# ESP32-H4 register map
Vendor: ESPRESSIF SYSTEMS (SHANGHAI) CO., LTD.; Series: ESP32 H-Series; File version: 1
CPU: RV32IMAC r0p0, little endian, no MPU, no FPU, 0 interrupt priority bits
Address unit: 32 bits
Registers are 32-bit, read-write, reset 0x0 unless marked. A register's access mark holds for its fields unless they carry their own. Offsets are from the block's base; [hi:lo] are bit positions; {n}, {i} and the like mark numbered series.

## DMA — DMA (Direct Memory Access) Controller
Base 0x6001F000
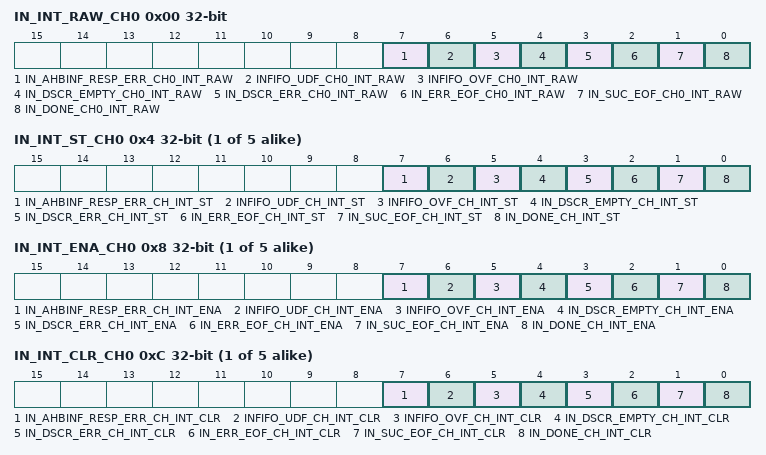
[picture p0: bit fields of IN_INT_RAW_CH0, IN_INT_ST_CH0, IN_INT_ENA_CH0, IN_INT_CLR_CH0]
0x00 IN_INT_RAW_CH0 — Raw interrupt status of RX channel 0
  [7] IN_AHBINF_RESP_ERR_CH0_INT_RAW — The raw interrupt status of AHB_DMA_IN_RESP_ERR_CH0_INT.
  [6] INFIFO_UDF_CH0_INT_RAW — The raw interrupt status of AHB_DMA_INFIFO_UDF_CH0_INT.
  [5] INFIFO_OVF_CH0_INT_RAW — The raw interrupt status of AHB_DMA_INFIFO_OVF_CH0_INT.
  [4] IN_DSCR_EMPTY_CH0_INT_RAW — The raw interrupt status of AHB_DMA_IN_DSCR_EMPTY_CH0_INT.
  [3] IN_DSCR_ERR_CH0_INT_RAW — The raw interrupt status of AHB_DMA_IN_DSCR_ERR_CH0_INT.
  [2] IN_ERR_EOF_CH0_INT_RAW — The raw interrupt status of AHB_DMA_IN_ERR_EOF_CH0_INT.
  [1] IN_SUC_EOF_CH0_INT_RAW — The raw interrupt status of AHB_DMA_IN_SUC_EOF_CH0_INT.
  [0] IN_DONE_CH0_INT_RAW — The raw interrupt status of AHB_DMA_IN_DONE_CH0_INT.
{0x4+0x10*i} IN_INT_ST_CH{i} (i=0..4) ro — Masked interrupt status of RX channel {i}
  [7] IN_AHBINF_RESP_ERR_CH_INT_ST — The masked interrupt status of AHB_DMA_IN_RESP_ERR_CH%s_INT.
  [6] INFIFO_UDF_CH_INT_ST — The masked interrupt status of AHB_DMA_INFIFO_UDF_CH%s_INT.
  [5] INFIFO_OVF_CH_INT_ST — The masked interrupt status of AHB_DMA_INFIFO_OVF_CH%s_INT.
  [4] IN_DSCR_EMPTY_CH_INT_ST — The masked interrupt status of AHB_DMA_IN_DSCR_EMPTY_CH%s_INT.
  [3] IN_DSCR_ERR_CH_INT_ST — The masked interrupt status of AHB_DMA_IN_DSCR_ERR_CH%s_INT.
  [2] IN_ERR_EOF_CH_INT_ST — The masked interrupt status of AHB_DMA_IN_ERR_EOF_CH%s_INT.
  [1] IN_SUC_EOF_CH_INT_ST — The masked interrupt status of AHB_DMA_IN_SUC_EOF_CH%s_INT.
  [0] IN_DONE_CH_INT_ST — The masked interrupt status of AHB_DMA_IN_DONE_CH%s_INT.
{0x8+0x10*i} IN_INT_ENA_CH{i} (i=0..4) — Interrupt enable bits of RX channel {i}
  [7] IN_AHBINF_RESP_ERR_CH_INT_ENA — Write 1 to enable AHB_DMA_IN_RESP_ERR_CH%s_INT.
  [6] INFIFO_UDF_CH_INT_ENA — Write 1 to enable AHB_DMA_INFIFO_UDF_CH%s_INT.
  [5] INFIFO_OVF_CH_INT_ENA — Write 1 to enable AHB_DMA_INFIFO_OVF_CH%s_INT.
  [4] IN_DSCR_EMPTY_CH_INT_ENA — Write 1 to enable AHB_DMA_IN_DSCR_EMPTY_CH%s_INT.
  [3] IN_DSCR_ERR_CH_INT_ENA — Write 1 to enable AHB_DMA_IN_DSCR_ERR_CH%s_INT.
  [2] IN_ERR_EOF_CH_INT_ENA — Write 1 to enable AHB_DMA_IN_ERR_EOF_CH%s_INT.
  [1] IN_SUC_EOF_CH_INT_ENA — Write 1 to enable AHB_DMA_IN_SUC_EOF_CH%s_INT.
  [0] IN_DONE_CH_INT_ENA — Write 1 to enable AHB_DMA_IN_DONE_CH%s_INT.
{0xC+0x10*i} IN_INT_CLR_CH{i} (i=0..4) wo — Interrupt clear bits of RX channel {i}
  [7] IN_AHBINF_RESP_ERR_CH_INT_CLR — Write 1 to clear AHB_DMA_IN_RESP_ERR_CH%s_INT.
  [6] INFIFO_UDF_CH_INT_CLR — Write 1 to clear AHB_DMA_INFIFO_UDF_CH%s_INT.
  [5] INFIFO_OVF_CH_INT_CLR — Write 1 to clear AHB_DMA_INFIFO_OVF_CH%s_INT.
  [4] IN_DSCR_EMPTY_CH_INT_CLR — Write 1 to clear AHB_DMA_IN_DSCR_EMPTY_CH%s_INT.
  [3] IN_DSCR_ERR_CH_INT_CLR — Write 1 to clear AHB_DMA_IN_DSCR_ERR_CH%s_INT.
  [2] IN_ERR_EOF_CH_INT_CLR — Write 1 to clear AHB_DMA_IN_ERR_EOF_CH%s_INT.
  [1] IN_SUC_EOF_CH_INT_CLR — Write 1 to clear AHB_DMA_IN_SUC_EOF_CH%s_INT.
  [0] IN_DONE_CH_INT_CLR — Write 1 to clear AHB_DMA_IN_DONE_CH%s_INT.
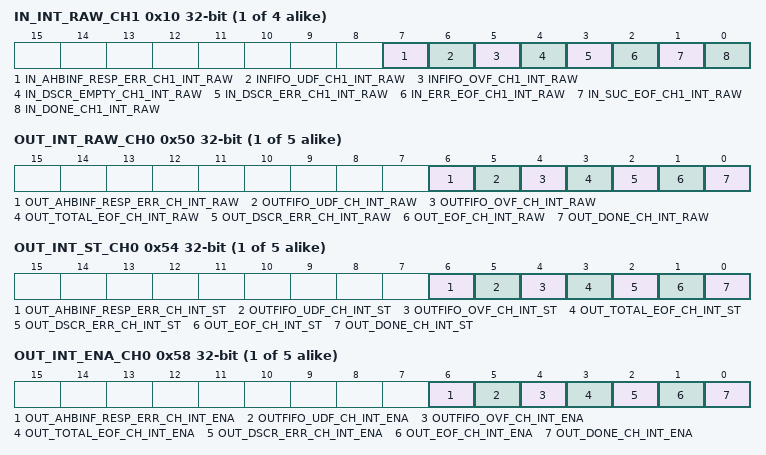
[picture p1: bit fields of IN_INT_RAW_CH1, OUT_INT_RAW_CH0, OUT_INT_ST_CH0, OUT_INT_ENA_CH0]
{0x0+0x10*i} IN_INT_RAW_CH{i} (i=1..4) — Raw interrupt status interrupt of RX channel {i}
  [7] IN_AHBINF_RESP_ERR_CH{i}_INT_RAW — The raw interrupt status of AHB_DMA_IN_RESP_ERR_CH{i}_INT.
  [6] INFIFO_UDF_CH{i}_INT_RAW — The raw interrupt status of AHB_DMA_INFIFO_UDF_CH{i}_INT.
  [5] INFIFO_OVF_CH{i}_INT_RAW — The raw interrupt status of AHB_DMA_INFIFO_OVF_CH{i}_INT.
  [4] IN_DSCR_EMPTY_CH{i}_INT_RAW — The raw interrupt status of AHB_DMA_IN_DSCR_EMPTY_CH{i}_INT.
  [3] IN_DSCR_ERR_CH{i}_INT_RAW — The raw interrupt status of AHB_DMA_IN_DSCR_ERR_CH{i}_INT.
  [2] IN_ERR_EOF_CH{i}_INT_RAW — The raw interrupt status of AHB_DMA_IN_ERR_EOF_CH{i}_INT.
  [1] IN_SUC_EOF_CH{i}_INT_RAW — The raw interrupt status of AHB_DMA_IN_SUC_EOF_CH{i}_INT.
  [0] IN_DONE_CH{i}_INT_RAW — The raw interrupt status of AHB_DMA_IN_DONE_CH{i}_INT.
{0x50+0x10*i} OUT_INT_RAW_CH{i} (i=0..4) — Raw interrupt status of TX channel {i}
  [6] OUT_AHBINF_RESP_ERR_CH_INT_RAW — The raw interrupt status of AHB_DMA_OUT_RESP_ERR_CH%s_INT.
  [5] OUTFIFO_UDF_CH_INT_RAW — The raw interrupt status of AHB_DMA_OUTFIFO_UDF_CH%s_INT.
  [4] OUTFIFO_OVF_CH_INT_RAW — The raw interrupt status of AHB_DMA_OUTFIFO_OVF_CH%s_INT.
  [3] OUT_TOTAL_EOF_CH_INT_RAW — The raw interrupt status of AHB_DMA_OUT_TOTAL_EOF_CH%s_INT.
  [2] OUT_DSCR_ERR_CH_INT_RAW — The raw interrupt status of AHB_DMA_OUT_DSCR_ERR_CH%s_INT.
  [1] OUT_EOF_CH_INT_RAW — The raw interrupt status of AHB_DMA_OUT_EOF_CH%s_INT.
  [0] OUT_DONE_CH_INT_RAW — The raw interrupt status of AHB_DMA_OUT_DONE_CH%s_INT.
{0x54+0x10*i} OUT_INT_ST_CH{i} (i=0..4) ro — Masked interrupt status of TX channel {i}
  [6] OUT_AHBINF_RESP_ERR_CH_INT_ST — The masked interrupt status of AHB_DMA_OUT_RESP_ERR_CH%s_INT.
  [5] OUTFIFO_UDF_CH_INT_ST — The masked interrupt status of AHB_DMA_OUTFIFO_UDF_CH%s_INT.
  [4] OUTFIFO_OVF_CH_INT_ST — The masked interrupt status of AHB_DMA_OUTFIFO_OVF_CH%s_INT.
  [3] OUT_TOTAL_EOF_CH_INT_ST — The masked interrupt status of AHB_DMA_OUT_TOTAL_EOF_CH%s_INT.
  [2] OUT_DSCR_ERR_CH_INT_ST — The masked interrupt status of AHB_DMA_OUT_DSCR_ERR_CH%s_INT.
  [1] OUT_EOF_CH_INT_ST — The masked interrupt status of AHB_DMA_OUT_EOF_CH%s_INT.
  [0] OUT_DONE_CH_INT_ST — The masked interrupt status of AHB_DMA_OUT_DONE_CH%s_INT.
{0x58+0x10*i} OUT_INT_ENA_CH{i} (i=0..4) — Interrupt enable bits of TX channel {i}
  [6] OUT_AHBINF_RESP_ERR_CH_INT_ENA — Write 1 to enable AHB_DMA_OUT_RESP_ERR_CH%s_INT.
  [5] OUTFIFO_UDF_CH_INT_ENA — Write 1 to enable AHB_DMA_OUTFIFO_UDF_CH%s_INT.
  [4] OUTFIFO_OVF_CH_INT_ENA — Write 1 to enable AHB_DMA_OUTFIFO_OVF_CH%s_INT.
  [3] OUT_TOTAL_EOF_CH_INT_ENA — Write 1 to enable AHB_DMA_OUT_TOTAL_EOF_CH%s_INT.
  [2] OUT_DSCR_ERR_CH_INT_ENA — Write 1 to enable AHB_DMA_OUT_DSCR_ERR_CH%s_INT.
  [1] OUT_EOF_CH_INT_ENA — Write 1 to enable AHB_DMA_OUT_EOF_CH%s_INT.
  [0] OUT_DONE_CH_INT_ENA — Write 1 to enable AHB_DMA_OUT_DONE_CH%s_INT.
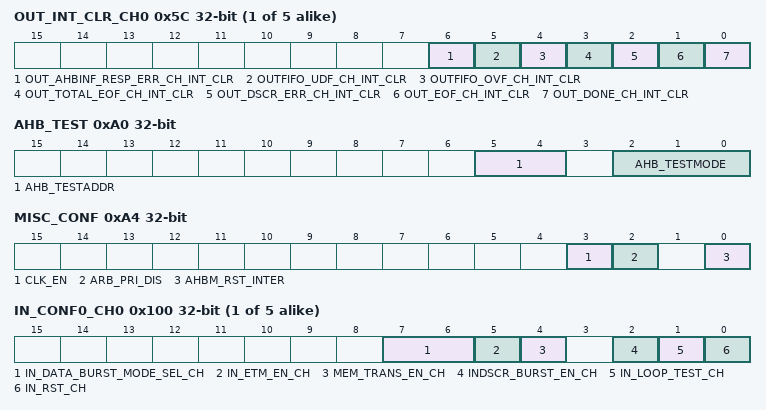
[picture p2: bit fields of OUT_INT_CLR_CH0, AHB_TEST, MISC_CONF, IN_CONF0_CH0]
{0x5C+0x10*i} OUT_INT_CLR_CH{i} (i=0..4) wo — Interrupt clear bits of TX channel {i}
  [6] OUT_AHBINF_RESP_ERR_CH_INT_CLR — Write 1 to clear AHB_DMA_OUT_RESP_ERR_CH%s_INT.
  [5] OUTFIFO_UDF_CH_INT_CLR — Write 1 to clear AHB_DMA_OUTFIFO_UDF_CH%s_INT.
  [4] OUTFIFO_OVF_CH_INT_CLR — Write 1 to clear AHB_DMA_OUTFIFO_OVF_CH%s_INT.
  [3] OUT_TOTAL_EOF_CH_INT_CLR — Write 1 to clear AHB_DMA_OUT_TOTAL_EOF_CH%s_INT.
  [2] OUT_DSCR_ERR_CH_INT_CLR — Write 1 to clear AHB_DMA_OUT_DSCR_ERR_CH%s_INT.
  [1] OUT_EOF_CH_INT_CLR — Write 1 to clear AHB_DMA_OUT_EOF_CH%s_INT.
  [0] OUT_DONE_CH_INT_CLR — Write 1 to clear AHB_DMA_OUT_DONE_CH%s_INT.
0xA0 AHB_TEST — reserved
  [5:4] AHB_TESTADDR — reserved
  [2:0] AHB_TESTMODE — reserved
0xA4 MISC_CONF — Miscellaneous register
  [3] CLK_EN — Configures clock gating.\\0: Support clock only when the application writes registers.\\ 1: Always force the clock on for registers.\\
  [2] ARB_PRI_DIS — Configures whether to disable the fixed-priority channel arbitration.\\0: Enable\\1: Disable\\
  [0] AHBM_RST_INTER — Write 1 and then 0 to reset the internal AHB FSM.
0xA8 DATE reset 0x2407310 — Version control register
  [31:0] DATE — Version control register.
{0x100+0x100*i} IN_CONF0_CH{i} (i=0..4) — Configuration register 0 of RX channel {i}
  [7:6] IN_DATA_BURST_MODE_SEL_CH — Configures max burst size for Rx channel%s.\\2'b00: single\\ 2'b01: incr4\\ 2'b10: incr8\\ 2'b11: incr16\\
  [5] IN_ETM_EN_CH — Configures whether to enable ETM control for RX channel%s.\\0: Disable\\1: Enable\\
  [4] MEM_TRANS_EN_CH — Configures whether to enable memory-to-memory data transfer.\\0: Disable\\1: Enable\\
  [2] INDSCR_BURST_EN_CH — Configures whether to enable INCR burst transfer for RX channel %s to read descriptors.\\0: Disable\\1: Enable\\
  [1] IN_LOOP_TEST_CH — Reserved.
  [0] IN_RST_CH — Write 1 and then 0 to reset AHB_DMA channel 0 RX FSM and RX FIFO pointer.
{0x104+0x100*i} IN_CONF1_CH{i} (i=0..4) — Configuration register 1 of RX channel {i}
  [12] IN_CHECK_OWNER_CH — Configures whether to enable owner bit check for RX channel %s.\\0: Disable\\1: Enable\\
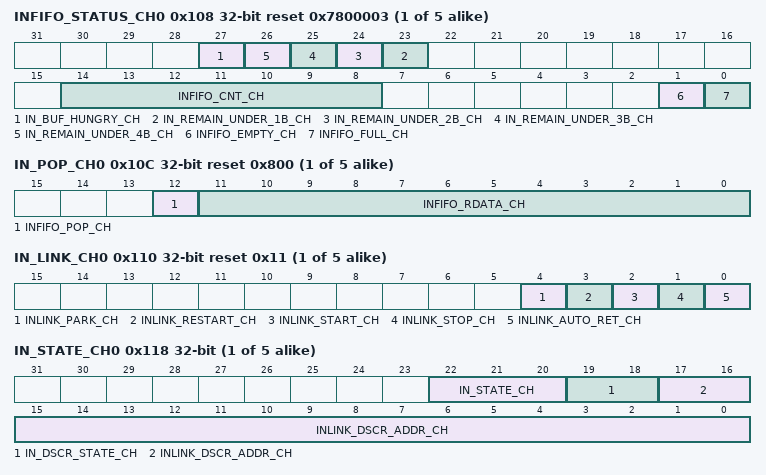
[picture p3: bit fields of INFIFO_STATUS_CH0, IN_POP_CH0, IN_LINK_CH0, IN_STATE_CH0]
{0x108+0x100*i} INFIFO_STATUS_CH{i} (i=0..4) ro reset 0x7800003 — Receive FIFO status of RX channel {i}
  [27] IN_BUF_HUNGRY_CH — reserved
  [n+22] IN_REMAIN_UNDER_{n}B_CH (n=1..4) — reserved
  [14:8] INFIFO_CNT_CH — Represents the number of data bytes in L1 RX FIFO for RX channel %s.
  [1] INFIFO_EMPTY_CH — Represents whether L1 RX FIFO is empty.\\0: Not empty\\1: Empty\\
  [0] INFIFO_FULL_CH — Represents whether L1 RX FIFO is full.\\0: Not Full\\1: Full\\
{0x10C+0x100*i} IN_POP_CH{i} (i=0..4) access per field reset 0x800 — Pop control register of RX channel {i}
  [12] INFIFO_POP_CH wo — Configures whether to pop data from AHB_DMA FIFO.\\0: Invalid. No effect\\1: Pop\\
  [11:0] INFIFO_RDATA_CH ro — Represents the data popped from AHB_DMA FIFO.
{0x110+0x100*i} IN_LINK_CH{i} (i=0..4) access per field reset 0x11 — Linked list descriptor configuration and control register of RX channel {i}
  [4] INLINK_PARK_CH ro — Represents the status of the receive descriptor's FSM.\\0: Running\\1: Idle\\
  [3] INLINK_RESTART_CH wo — Configures whether to restart RX channel %s for AHB_DMA transfer.\\0: Invalid. No effect\\1: Restart\\
  [2] INLINK_START_CH wo — Configures whether to enable AHB_DMA's RX channel %s for data transfer.\\0: Disable\\1: Enable\\
  [1] INLINK_STOP_CH wo — Configures whether to stop AHB_DMA's RX channel %s from receiving data.\\0: Invalid. No effect\\1: Stop\\
  [0] INLINK_AUTO_RET_CH rw — Configures whether to return to current receive descriptor's address when there are some errors in current receiving data.\\0: Not return\\1: Return\\
{0x114+0x100*i} IN_LINK_ADDR_CH{i} (i=0..4) — Link list descriptor address configuration of RX channel {i}
  [31:0] INLINK_ADDR_CH — Configures the 32 bits of the first receive descriptor's address.
{0x118+0x100*i} IN_STATE_CH{i} (i=0..4) ro — Receive status of RX channel {i}
  [22:20] IN_STATE_CH — reserved
  [19:18] IN_DSCR_STATE_CH — reserved
  [17:0] INLINK_DSCR_ADDR_CH — Represents the address of the lower 18 bits of the next receive descriptor to be processed.
{0x11C+0x100*i} IN_SUC_EOF_DES_ADDR_CH{i} (i=0..4) ro — Receive descriptor address when EOF occurs on RX channel {i}
  [31:0] IN_SUC_EOF_DES_ADDR_CH — Represents the address of the receive descriptor when the EOF bit in this descriptor is 1.
{0x120+0x100*i} IN_ERR_EOF_DES_ADDR_CH{i} (i=0..4) ro — Receive descriptor address when errors occur of RX channel {i}
  [31:0] IN_ERR_EOF_DES_ADDR_CH — Represents the address of the receive descriptor when there are some errors in the currently received data.
0x124 IN_DONE_DES_ADDR_CH0 ro — RX_done Inlink descriptor address of RX channel 0
  [31:0] IN_DONE_DES_ADDR_CH0 — Represents the address of the inlink descriptor when this descriptor is completed .
{0x128+0x100*i} IN_DSCR_CH{i} (i=0..4) ro — Current receive descriptor address of RX channel {i}
  [31:0] INLINK_DSCR_CH — Represents the address of the next receive descriptor x+1 pointed by the current receive descriptor that has already been fetched.
{0x12C+0x100*i} IN_DSCR_BF0_CH{i} (i=0..4) ro — The last receive descriptor address of RX channel {i}
  [31:0] INLINK_DSCR_BF0_CH — Represents the address of the current receive descriptor x that has already been fetched.
{0x130+0x100*i} IN_DSCR_BF1_CH{i} (i=0..4) ro — The second-to-last receive descriptor address of RX channel {i}
  [31:0] INLINK_DSCR_BF1_CH — Represents the address of the previous receive descriptor x-1 that has already been fetched.
{0x134+0x100*i} IN_PRI_CH{i} (i=0..4) — Priority register of RX channel {i}
  [3:0] RX_PRI_CH — Configures the priority of RX channel %s.The larger of the value, the higher of the priority.
{0x138+0x100*i} IN_PERI_SEL_CH{i} (i=0..4) reset 0x3F — Peripheral selection register of RX channel {i}
  [5:0] PERI_IN_SEL_CH — Configures the peripheral connected to RX channel %s.\\ 0: SPI3\\ 1: SPI2\\ 2: UHCI0\\ 3: I2S0\\ 4: AES\\ 5: Sample_rate_convert-0\\ 6: Sample_rate_convert-1\\ 7: SHA\\ 8: ADC_DAC\\ 9: PARL_IO\\ 10: Dummy\\ 11~15: Dummy\\
{0x13C+0x100*i} RX_CH_ARB_WEIGH_CH{i} (i=0..4) — RX channel {i} arbitration weight configuration register
  [3:0] RX_CH_ARB_WEIGH_CH — Configures the weight(i.e the number of tokens) of RX channel%s
{0x140+0x100*i} RX_ARB_WEIGH_OPT_DIR_CH{i} (i=0..4) — RX channel {i} weight arbitration optimization enable register
  [0] RX_ARB_WEIGH_OPT_DIR_CH — reserved
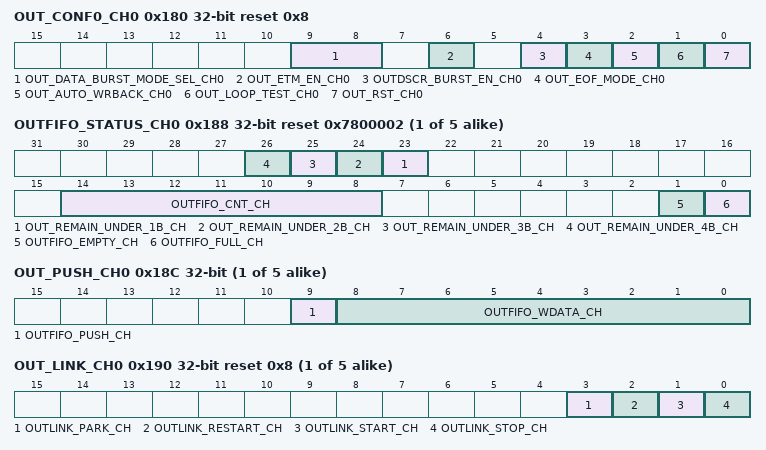
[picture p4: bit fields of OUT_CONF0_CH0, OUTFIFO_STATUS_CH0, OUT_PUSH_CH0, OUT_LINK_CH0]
0x180 OUT_CONF0_CH0 reset 0x8 — Configuration register 0 of TX channel 0
  [9:8] OUT_DATA_BURST_MODE_SEL_CH0 — Configures max burst size for TX channel0.\\2'b00: single\\ 2'b01: incr4\\ 2'b10: incr8\\ 2'b11: incr16\\
  [6] OUT_ETM_EN_CH0 — Configures whether to enable ETM control for TX channel 0.\\0: Disable\\1: Enable\\
  [4] OUTDSCR_BURST_EN_CH0 — Configures whether to enable INCR burst transfer for TX channel 0 reading descriptors.\\0: Disable\\1: Enable\\
  [3] OUT_EOF_MODE_CH0 — Configures when to generate EOF flag.\\0: EOF flag for TX channel 0 is generated when data to be transmitted has been pushed into FIFO in AHB_DMA.\\ 1: EOF flag for TX channel 0 is generated when data to be transmitted has been popped from FIFO in AHB_DMA.\\
  [2] OUT_AUTO_WRBACK_CH0 — Configures whether to enable automatic outlink write-back when all the data in TX FIFO has been transmitted.\\0: Disable\\1: Enable\\
  [1] OUT_LOOP_TEST_CH0 — Reserved.
  [0] OUT_RST_CH0 — Configures the reset state of AHB_DMA channel 0 TX FSM and TX FIFO pointer.\\0: Release reset\\1: Reset\\
{0x184+0x100*i} OUT_CONF1_CH{i} (i=0..4) — Configuration register 1 of TX channel {i}
  [12] OUT_CHECK_OWNER_CH — Configures whether to enable owner bit check for TX channel %s.\\0: Disable\\1: Enable\\
{0x188+0x100*i} OUTFIFO_STATUS_CH{i} (i=0..4) ro reset 0x7800002 — Transmit FIFO status of TX channel {i}
  [n+22] OUT_REMAIN_UNDER_{n}B_CH (n=1..4) — Reserved.
  [14:8] OUTFIFO_CNT_CH — Represents the number of data bytes in L1 TX FIFO for TX channel %s.
  [1] OUTFIFO_EMPTY_CH — Represents whether L1 TX FIFO is empty.\\0: Not empty\\1: Empty\\
  [0] OUTFIFO_FULL_CH — Represents whether L1 TX FIFO is full.\\0: Not Full\\1: Full\\
{0x18C+0x100*i} OUT_PUSH_CH{i} (i=0..4) access per field — Push control register of TX channel {i}
  [9] OUTFIFO_PUSH_CH wo — Configures whether to push data into AHB_DMA FIFO.\\0: Invalid. No effect\\1: Push\\
  [8:0] OUTFIFO_WDATA_CH rw — Configures the data that need to be pushed into AHB_DMA FIFO.
{0x190+0x100*i} OUT_LINK_CH{i} (i=0..4) access per field reset 0x8 — Linked list descriptor configuration and control register of TX channel {i}
  [3] OUTLINK_PARK_CH ro — Represents the status of the transmit descriptor's FSM.\\0: Running\\1: Idle\\
  [2] OUTLINK_RESTART_CH wo — Configures whether to restart TX channel %s for AHB_DMA transfer.\\0: Invalid. No effect\\1: Restart\\
  [1] OUTLINK_START_CH wo — Configures whether to enable AHB_DMA's TX channel %s for data transfer.\\0: Disable\\1: Enable\\
  [0] OUTLINK_STOP_CH wo — Configures whether to stop AHB_DMA's TX channel %s from transmitting data.\\0: Invalid. No effect\\1: Stop\\
{0x194+0x100*i} OUT_LINK_ADDR_CH{i} (i=0..4) — Link list descriptor address configuration of TX channel {i}
  [31:0] OUTLINK_ADDR_CH — Configures the 32 bits of the first receive descriptor's address.
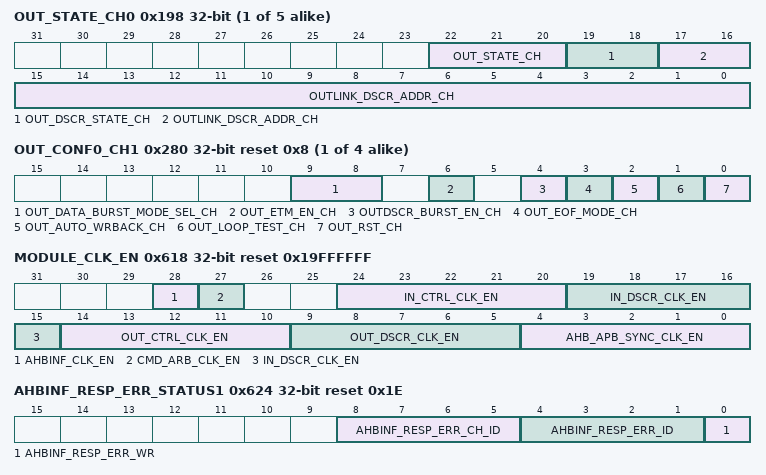
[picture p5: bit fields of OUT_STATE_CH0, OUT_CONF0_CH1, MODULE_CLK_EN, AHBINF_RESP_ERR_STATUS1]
{0x198+0x100*i} OUT_STATE_CH{i} (i=0..4) ro — Transmit status of TX channel {i}
  [22:20] OUT_STATE_CH — reserved
  [19:18] OUT_DSCR_STATE_CH — reserved
  [17:0] OUTLINK_DSCR_ADDR_CH — Represents the lower 18 bits of the address of the next transmit descriptor to be processed.
{0x19C+0x100*i} OUT_EOF_DES_ADDR_CH{i} (i=0..4) ro — Transmit descriptor address when EOF occurs on TX channel {i}
  [31:0] OUT_EOF_DES_ADDR_CH — Represents the address of the transmit descriptor when the EOF bit in this descriptor is 1.
{0x1A0+0x100*i} OUT_EOF_BFR_DES_ADDR_CH{i} (i=0..4) ro — The last transmit descriptor address when EOF occurs on TX channel {i}
  [31:0] OUT_EOF_BFR_DES_ADDR_CH — Represents the address of the transmit descriptor before the last transmit descriptor.
{0x1A4+0x100*i} OUT_DONE_DES_ADDR_CH{i} (i=0..4) ro — TX done outlink descriptor address of TX channel {i}
  [31:0] OUT_DONE_DES_ADDR_CH — Represents the address of the outlink descriptor when this descriptor is completed.
{0x1A8+0x100*i} OUT_DSCR_CH{i} (i=0..4) ro — Current transmit descriptor address of TX channel {i}
  [31:0] OUTLINK_DSCR_CH — Represents the address of the next transmit descriptor y+1 pointed by the current transmit descriptor that has already been fetched.
{0x1AC+0x100*i} OUT_DSCR_BF0_CH{i} (i=0..4) ro — The last transmit descriptor address of TX channel {i}
  [31:0] OUTLINK_DSCR_BF0_CH — Represents the address of the current transmit descriptor y that has already been fetched.
{0x1B0+0x100*i} OUT_DSCR_BF1_CH{i} (i=0..4) ro — The second-to-last transmit descriptor address of TX channel {i}
  [31:0] OUTLINK_DSCR_BF1_CH — Represents the address of the previous transmit descriptor y-1 that has already been fetched.
{0x1B4+0x100*i} OUT_PRI_CH{i} (i=0..4) — Priority register of TX channel {i}
  [3:0] TX_PRI_CH — Configures the priority of TX channel %s.The larger of the value, the higher of the priority.
{0x1B8+0x100*i} OUT_PERI_SEL_CH{i} (i=0..4) reset 0x3F — Peripheral selection register of TX channel {i}
  [5:0] PERI_OUT_SEL_CH — Configures the peripheral connected to TX channel %s.\\ 0: SPI3\\ 1: SPI2\\ 2: UHCI0\\ 3: I2S0\\ 4: AES\\ 5: Sample_rate_convert-0\\ 6: Sample_rate_convert-1\\ 7: SHA\\ 8: ADC_DAC\\ 9: PARL_IO\\ 10: Dummy\\ 11~15: Dummy\\
{0x1BC+0x100*i} TX_CH_ARB_WEIGH_CH{i} (i=0..4) — TX channel {i} arbitration weight configuration register
  [3:0] TX_CH_ARB_WEIGH_CH — Configures the weight(i.e the number of tokens) of TX channel%s
{0x1C0+0x100*i} TX_ARB_WEIGH_OPT_DIR_CH{i} (i=0..4) — TX channel {i} weight arbitration optimization enable register
  [0] TX_ARB_WEIGH_OPT_DIR_CH — reserved
{0x124+0x100*i} IN_DONE_DES_ADDR_CH{i} ro (i=1..4) — RX_done inlink descriptor address of RX channel {i}
  [31:0] IN_DONE_DES_ADDR_CH{i} — Represents the address of the inlink descriptor when this descriptor is completed.
{0x180+0x100*i} OUT_CONF0_CH{i} (i=1..4) reset 0x8 — Configuration register 0 of TX channel {i}
  [9:8] OUT_DATA_BURST_MODE_SEL_CH — Configures max burst size for TX channel%s.\\2'b00: single\\ 2'b01: incr4\\ 2'b10: incr8\\ 2'b11: incr16\\
  [6] OUT_ETM_EN_CH — Configures whether to enable ETM control for TX channel %s.\\0: Disable\\1: Enable\\
  [4] OUTDSCR_BURST_EN_CH — Configures whether to enable INCR burst transfer for TX channel %s reading descriptors.\\0: Disable\\1: Enable\\
  [3] OUT_EOF_MODE_CH — Configures when to generate EOF flag.\\0: EOF flag for TX channel %s is generated when data to be transmitted has been pushed into FIFO in AHB_DMA.\\ 1: EOF flag for TX channel %s is generated when data to be transmitted has been popped from FIFO in AHB_DMA.\\
  [2] OUT_AUTO_WRBACK_CH — Configures whether to enable automatic outlink write-back when all the data in TX FIFO has been transmitted.\\0: Disable\\1: Enable\\
  [1] OUT_LOOP_TEST_CH — Reserved.
  [0] OUT_RST_CH — Configures the reset state of AHB_DMA channel %s TX FSM and TX FIFO pointer.\\0: Release reset\\1: Reset\\
0x600 INTR_MEM_START_ADDR — Accessible address space start address configuration register
  [31:0] ACCESS_INTR_MEM_START_ADDR — Configures the start address of accessible address space.
0x604 INTR_MEM_END_ADDR reset 0xFFFFFFFF — Accessible address space end address configuration register
  [31:0] ACCESS_INTR_MEM_END_ADDR — Configures the end address of accessible address space.
0x608 ARB_TIMEOUT — TX arbitration timeout configuration register
  [15:0] ARB_TIMEOUT — Configures the time slot. Measurement unit: AHB bus clock cycle.
0x610 WEIGHT_EN — TX weight arbitration enable register
  [0] WEIGHT_EN — Configures whether to enable weight arbitration.\\0: Disable\\1: Enable\\
0x618 MODULE_CLK_EN reset 0x19FFFFFF — Module clock force on register
  [28] AHBINF_CLK_EN — Configures whether to force on ahbinf module clock. \\0 : Not force on ahbinf clock \\1 : Force on ahbinf clock\\
  [27] CMD_ARB_CLK_EN — Configures whether to force on cmd_arb module clock. \\0 : Not force on cmd_arb clock \\1 : Force on cmd_arb clock\\
  [24:20] IN_CTRL_CLK_EN — Configures whether to force on in_ctrl 4~0 module clock. For bit n:\\0 : Not force on in_ctrl n clock \\1 : Force on in_ctrl n clock\\
  [19:15] IN_DSCR_CLK_EN — Configures whether to force on in_dscr 4~0 module clock. For bit n:\\0 : Not force on in_dscr n clock \\1 : Force on in_dscr n clock\\
  [14:10] OUT_CTRL_CLK_EN — Configures whether to force on out_ctrl 4~0 module clock. For bit n:\\0 : Not force on out_ctrl n clock \\1 : Force on out_ctrl n clock\\
  [9:5] OUT_DSCR_CLK_EN — Configures whether to force on out_dscr 4~0 module clock. For bit n:\\0 : Not force on out_dscr n clock \\1 : Force on out_dscr n clock\\
  [4:0] AHB_APB_SYNC_CLK_EN — Configures whether to force on ahb_apb_sync 4~0 module clock. For bit n:\\0 : Not force on ahb_apb_sync n clock \\1 : Force on ahb_apb_sync n clock\\
0x620 AHBINF_RESP_ERR_STATUS0 ro — AHB response error status 0 register
  [31:0] AHBINF_RESP_ERR_ADDR — Represents the address of the AHB response error.
0x624 AHBINF_RESP_ERR_STATUS1 ro reset 0x1E — AHB response error status 1 register
  [8:5] AHBINF_RESP_ERR_CH_ID — Represents the AHB response error request channel id.bit[3]=1:TX channel.\\bit[3]=0:RX channel.\\
  [4:1] AHBINF_RESP_ERR_ID — Represents the AHB response error request id.
  [0] AHBINF_RESP_ERR_WR — Represents the AHB response error is write request.

## Notices in the file
Copyright 2026 Espressif Systems (Shanghai) PTE LTD
Licensed under the Apache License, Version 2.0 (the "License");
you may not use this file except in compliance with the License.
You may obtain a copy of the License at
http://www.apache.org/licenses/LICENSE-2.0
Unless required by applicable law or agreed to in writing, software
distributed under the License is distributed on an "AS IS" BASIS,
WITHOUT WARRANTIES OR CONDITIONS OF ANY KIND, either express or implied.
See the License for the specific language governing permissions and
limitations under the License.
